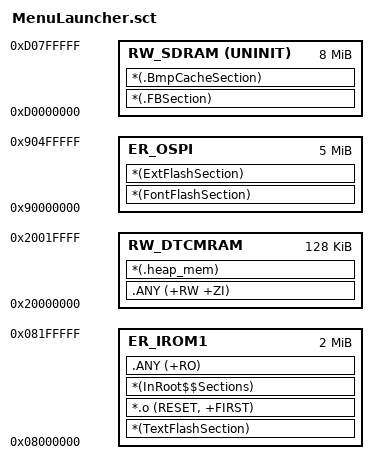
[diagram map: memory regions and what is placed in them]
; *************************************************************
; *** Scatter-Loading Description File generated by uVision ***
; *************************************************************

LR_IROM1 0x08000000 0x00200000  {    ; load region size_region
 ER_IROM1 0x08000000 0x00200000 {
   *(TextFlashSection)
     *.o (RESET, +FIRST)
   *(InRoot$$Sections)
		.ANY (+RO)
}

   RW_DTCMRAM 0x20000000  0x00020000 { ; RW data
 .ANY (+RW +ZI)
  *(.heap_mem)
}


}

LR_OSPI 0x90000000 0x500000  {    ; load region size_region
  ER_OSPI 0x90000000 0x500000 {
    *(FontFlashSection)
    *(ExtFlashSection)

  }
   RW_SDRAM 0xD0000000 UNINIT  0x800000  {  ; RW data
 *(.FBSection)
 *(.BmpCacheSection)
   } 
}  
 



 

